AUTOSAR XML (schema 00044)
package /ComponentTypes
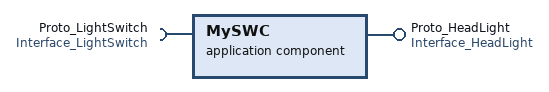
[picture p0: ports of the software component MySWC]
  application sw component type MySWC
    require port Proto_LightSwitch: nonqueued-receiver-com-spec{data-element=DE_LightSwitch, init-value=0}, required-interface=Interface_LightSwitch
    provide port Proto_HeadLight: nonqueued-sender-com-spec=DE_HeadLight, provided-interface=Interface_HeadLight
    behavior MySWC_InternalBehavior
  swc implementation MySWC_Implementation: behavior=MySWC_InternalBehavior
